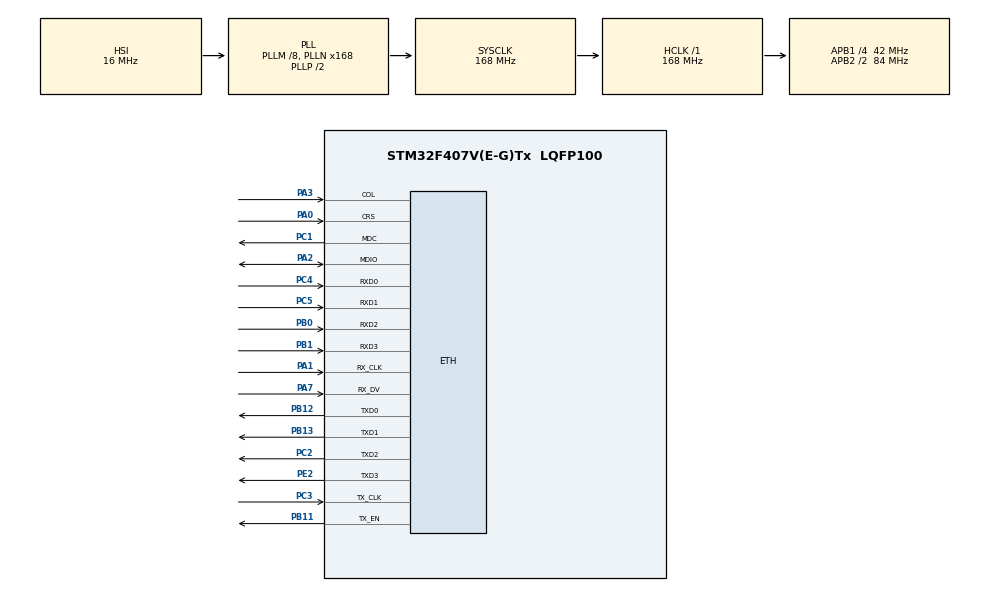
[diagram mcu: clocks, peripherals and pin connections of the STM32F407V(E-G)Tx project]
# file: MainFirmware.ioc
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ETH.MediaInterface=HAL_ETH_MII_MODE
LWIP.BSP.number=1
LWIP.IP_ADDRESS=192.168.010.200
LWIP.LWIP_DHCP=0
LWIP.NETMASK_ADDRESS=255.255.255.000
LWIP.Version=v2.1.2_Cube
LWIP0.BSP.STBoard=false
LWIP0.BSP.api=BSP_COMPONENT_DRIVER
LWIP0.BSP.component=DP83848
LWIP0.BSP.instance=DP83848
LWIP0.BSP.name=Driver_PHY
LWIP0.BSP.semaphore=S_DP83848
LWIP0.BSP.solution=DP83848
Mcu.Family=STM32F4
Mcu.Name=STM32F407V(E-G)Tx
Mcu.Package=LQFP100
NVIC.PriorityGroup=NVIC_PRIORITYGROUP_4
PA0-WKUP.Mode=MII
PA0-WKUP.Signal=ETH_CRS
PA1.Mode=MII
PA1.Signal=ETH_RX_CLK
PA2.Mode=MII
PA2.Signal=ETH_MDIO
PA3.Mode=MII
PA3.Signal=ETH_COL
PA7.Mode=MII
PA7.Signal=ETH_RX_DV
PB0.Mode=MII
PB0.Signal=ETH_RXD2
PB1.Mode=MII
PB1.Signal=ETH_RXD3
PB11.Mode=MII
PB11.Signal=ETH_TX_EN
PB12.Mode=MII
PB12.Signal=ETH_TXD0
PB13.Mode=MII
PB13.Signal=ETH_TXD1
PC1.Mode=MII
PC1.Signal=ETH_MDC
PC2.Mode=MII
PC2.Signal=ETH_TXD2
PC3.Mode=MII
PC3.Signal=ETH_TX_CLK
PC4.Mode=MII
PC4.Signal=ETH_RXD0
PC5.Mode=MII
PC5.Signal=ETH_RXD1
PE2.Mode=MII
PE2.Signal=ETH_TXD3
PH0-OSC_IN.Mode=HSE-External-Oscillator
PH0-OSC_IN.Signal=RCC_OSC_IN
PH1-OSC_OUT.Mode=HSE-External-Oscillator
PH1-OSC_OUT.Signal=RCC_OSC_OUT
ProjectManager.HeapSize=0x200
ProjectManager.StackSize=0x400
ProjectManager.TargetToolchain=STM32CubeIDE
RCC.48MHZClocksFreq_Value=84000000
RCC.AHBFreq_Value=168000000
RCC.APB1CLKDivider=RCC_HCLK_DIV4
RCC.APB1Freq_Value=42000000
RCC.APB1TimFreq_Value=84000000
RCC.APB2CLKDivider=RCC_HCLK_DIV2
RCC.APB2Freq_Value=84000000
RCC.APB2TimFreq_Value=168000000
RCC.CortexFreq_Value=168000000
RCC.HCLKFreq_Value=168000000
RCC.HSE_VALUE=25000000
RCC.HSI_VALUE=16000000
RCC.LSE_VALUE=32768
RCC.PLLM=8
RCC.PLLN=168
RCC.SYSCLKFreq_VALUE=168000000
RCC.SYSCLKSource=RCC_SYSCLKSOURCE_PLLCLK
RCC.VCOOutputFreq_Value=336000000
VP_IWDG_VS_IWDG.Mode=IWDG_Activate
VP_LWIP_VS_Enabled.Mode=Enabled
board=custom

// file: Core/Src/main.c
/* USER CODE BEGIN Header */
/**
  ******************************************************************************
  * @file           : main.c
  * @brief          : Main program body
  ******************************************************************************
  * @attention
  *
  * Copyright (c) 2025 STMicroelectronics.
  * All rights reserved.
  *
  * This software is licensed under terms that can be found in the LICENSE file
  * in the root directory of this software component.
  * If no LICENSE file comes with this software, it is provided AS-IS.
  *
  ******************************************************************************
  */
/* USER CODE END Header */
#include "main.h"
#include "iwdg.h"
#include "lwip.h"
#include "gpio.h"

/* USER CODE BEGIN Includes */
#include "flash_if.h"
/* USER CODE END Includes */

/* USER CODE BEGIN PD */
#define TEM_MEMORY_START			ADDR_FLASH_SECTOR_5											/* Start @ of user Flash area */
#define TEMP_MEMORY_STOP    		ADDR_FLASH_SECTOR_7  +  GetSectorSize(FLASH_SECTOR_7) -1 	/* End @ of user Flash area : sector start address + sector size -1 */
#define INFORMATION_MEMORY			ADDR_FLASH_SECTOR_11
#define MAIN_MEMORY					ADDR_FLASH_SECTOR_8
/* USER CODE END PD */

void SystemClock_Config(void);

int main(void)
{

  /* USER CODE BEGIN 1 */
	SCB->VTOR = (uint32_t)MAIN_MEMORY;
  /* USER CODE END 1 */

  /* MCU Configuration--------------------------------------------------------*/

  /* Reset of all peripherals, Initializes the Flash interface and the Systick. */
  HAL_Init();

  /* USER CODE BEGIN Init */
  /*Activate mask fault*/
  SCB->SHCSR |= SCB_SHCSR_MEMFAULTENA_Msk;
  SCB->SHCSR |= SCB_SHCSR_BUSFAULTACT_Msk;
  SCB->SHCSR |= SCB_SHCSR_USGFAULTENA_Msk;
  /* USER CODE END Init */

  /* Configure the system clock */
  SystemClock_Config();

  /* Initialize all configured peripherals */
  MX_GPIO_Init();
  MX_IWDG_Init();
  MX_LWIP_Init();

  /* Infinite loop */
  while (1)
  {

  }
}

void SystemClock_Config(void)
{
  RCC_OscInitTypeDef RCC_OscInitStruct = {0};
  RCC_ClkInitTypeDef RCC_ClkInitStruct = {0};

  /** Configure the main internal regulator output voltage
  */
  __HAL_RCC_PWR_CLK_ENABLE();
  __HAL_PWR_VOLTAGESCALING_CONFIG(PWR_REGULATOR_VOLTAGE_SCALE1);

  /** Initializes the RCC Oscillators according to the specified parameters
  * in the RCC_OscInitTypeDef structure.
  */
  RCC_OscInitStruct.OscillatorType = RCC_OSCILLATORTYPE_HSI|RCC_OSCILLATORTYPE_LSI;
  RCC_OscInitStruct.HSIState = RCC_HSI_ON;
  RCC_OscInitStruct.HSICalibrationValue = RCC_HSICALIBRATION_DEFAULT;
  RCC_OscInitStruct.LSIState = RCC_LSI_ON;
  RCC_OscInitStruct.PLL.PLLState = RCC_PLL_ON;
  RCC_OscInitStruct.PLL.PLLSource = RCC_PLLSOURCE_HSI;
  RCC_OscInitStruct.PLL.PLLM = 8;
  RCC_OscInitStruct.PLL.PLLN = 168;
  RCC_OscInitStruct.PLL.PLLP = RCC_PLLP_DIV2;
  RCC_OscInitStruct.PLL.PLLQ = 4;
  if (HAL_RCC_OscConfig(&RCC_OscInitStruct) != HAL_OK)
  {
    Error_Handler();
  }

  /** Initializes the CPU, AHB and APB buses clocks
  */
  RCC_ClkInitStruct.ClockType = RCC_CLOCKTYPE_HCLK|RCC_CLOCKTYPE_SYSCLK
                              |RCC_CLOCKTYPE_PCLK1|RCC_CLOCKTYPE_PCLK2;
  RCC_ClkInitStruct.SYSCLKSource = RCC_SYSCLKSOURCE_PLLCLK;
  RCC_ClkInitStruct.AHBCLKDivider = RCC_SYSCLK_DIV1;
  RCC_ClkInitStruct.APB1CLKDivider = RCC_HCLK_DIV4;
  RCC_ClkInitStruct.APB2CLKDivider = RCC_HCLK_DIV2;

  if (HAL_RCC_ClockConfig(&RCC_ClkInitStruct, FLASH_LATENCY_5) != HAL_OK)
  {
    Error_Handler();
  }
}

void Error_Handler(void)
{
  __disable_irq();
  while (1)
  {
  }
}
